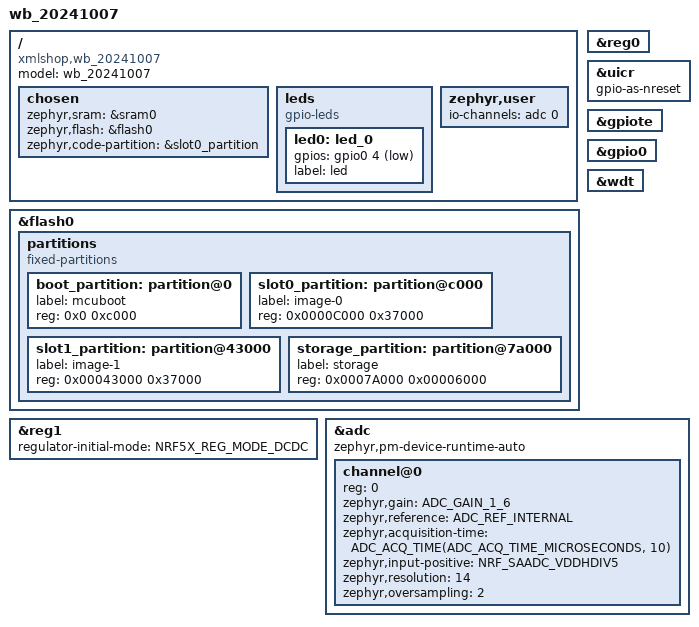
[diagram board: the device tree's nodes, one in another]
// Copyright (c) 2024 Nordic Semiconductor ASA
// SPDX-License-Identifier: Apache-2.0

/dts-v1/;
#include <nordic/nrf52833_qdaa.dtsi>
#include <zephyr/dt-bindings/input/input-event-codes.h>

/ {
	model = "wb_20241007";
	compatible = "xmlshop,wb_20241007";

	chosen {
		zephyr,sram = &sram0;
		zephyr,flash = &flash0;
		zephyr,code-partition = &slot0_partition;
	};

	leds {
		compatible = "gpio-leds";
		led0: led_0 {
			gpios = <&gpio0 4 GPIO_ACTIVE_LOW>;
			label = "led";
		};
	};

  zephyr,user {
    io-channels = <&adc 0>;
  };
};

&flash0 {
	partitions {
		compatible = "fixed-partitions";
		#address-cells = <1>;
		#size-cells = <1>;

		boot_partition: partition@0 {
			label = "mcuboot";
			reg = <0x0 0xc000>;
		};
		slot0_partition: partition@c000 {
			label = "image-0";
			reg = <0x0000C000 0x37000>;
		};
		slot1_partition: partition@43000 {
			label = "image-1";
			reg = <0x00043000 0x37000>;
		};
		storage_partition: partition@7a000 {
			label = "storage";
			reg = <0x0007A000 0x00006000>;
		};
	};
};

&reg0 {
  status = "okay";
};

&reg1 {
	regulator-initial-mode = <NRF5X_REG_MODE_DCDC>;
};

&uicr {
	gpio-as-nreset;
};
&gpiote {
	status = "okay";
};

&gpio0 {
	status = "okay";
};

&wdt {
  status = "okay";
};

&adc {
  #address-cells = <1>;
  #size-cells = <0>;
  status="okay";

  channel@0 {
    reg = <0>;
    zephyr,gain = "ADC_GAIN_1_6";
    zephyr,reference = "ADC_REF_INTERNAL";
    zephyr,acquisition-time = <ADC_ACQ_TIME(ADC_ACQ_TIME_MICROSECONDS, 10)>;
    zephyr,input-positive = <NRF_SAADC_VDDHDIV5>;
    zephyr,resolution = <14>;
    zephyr,oversampling = <2>;
  };

  zephyr,pm-device-runtime-auto;
};

